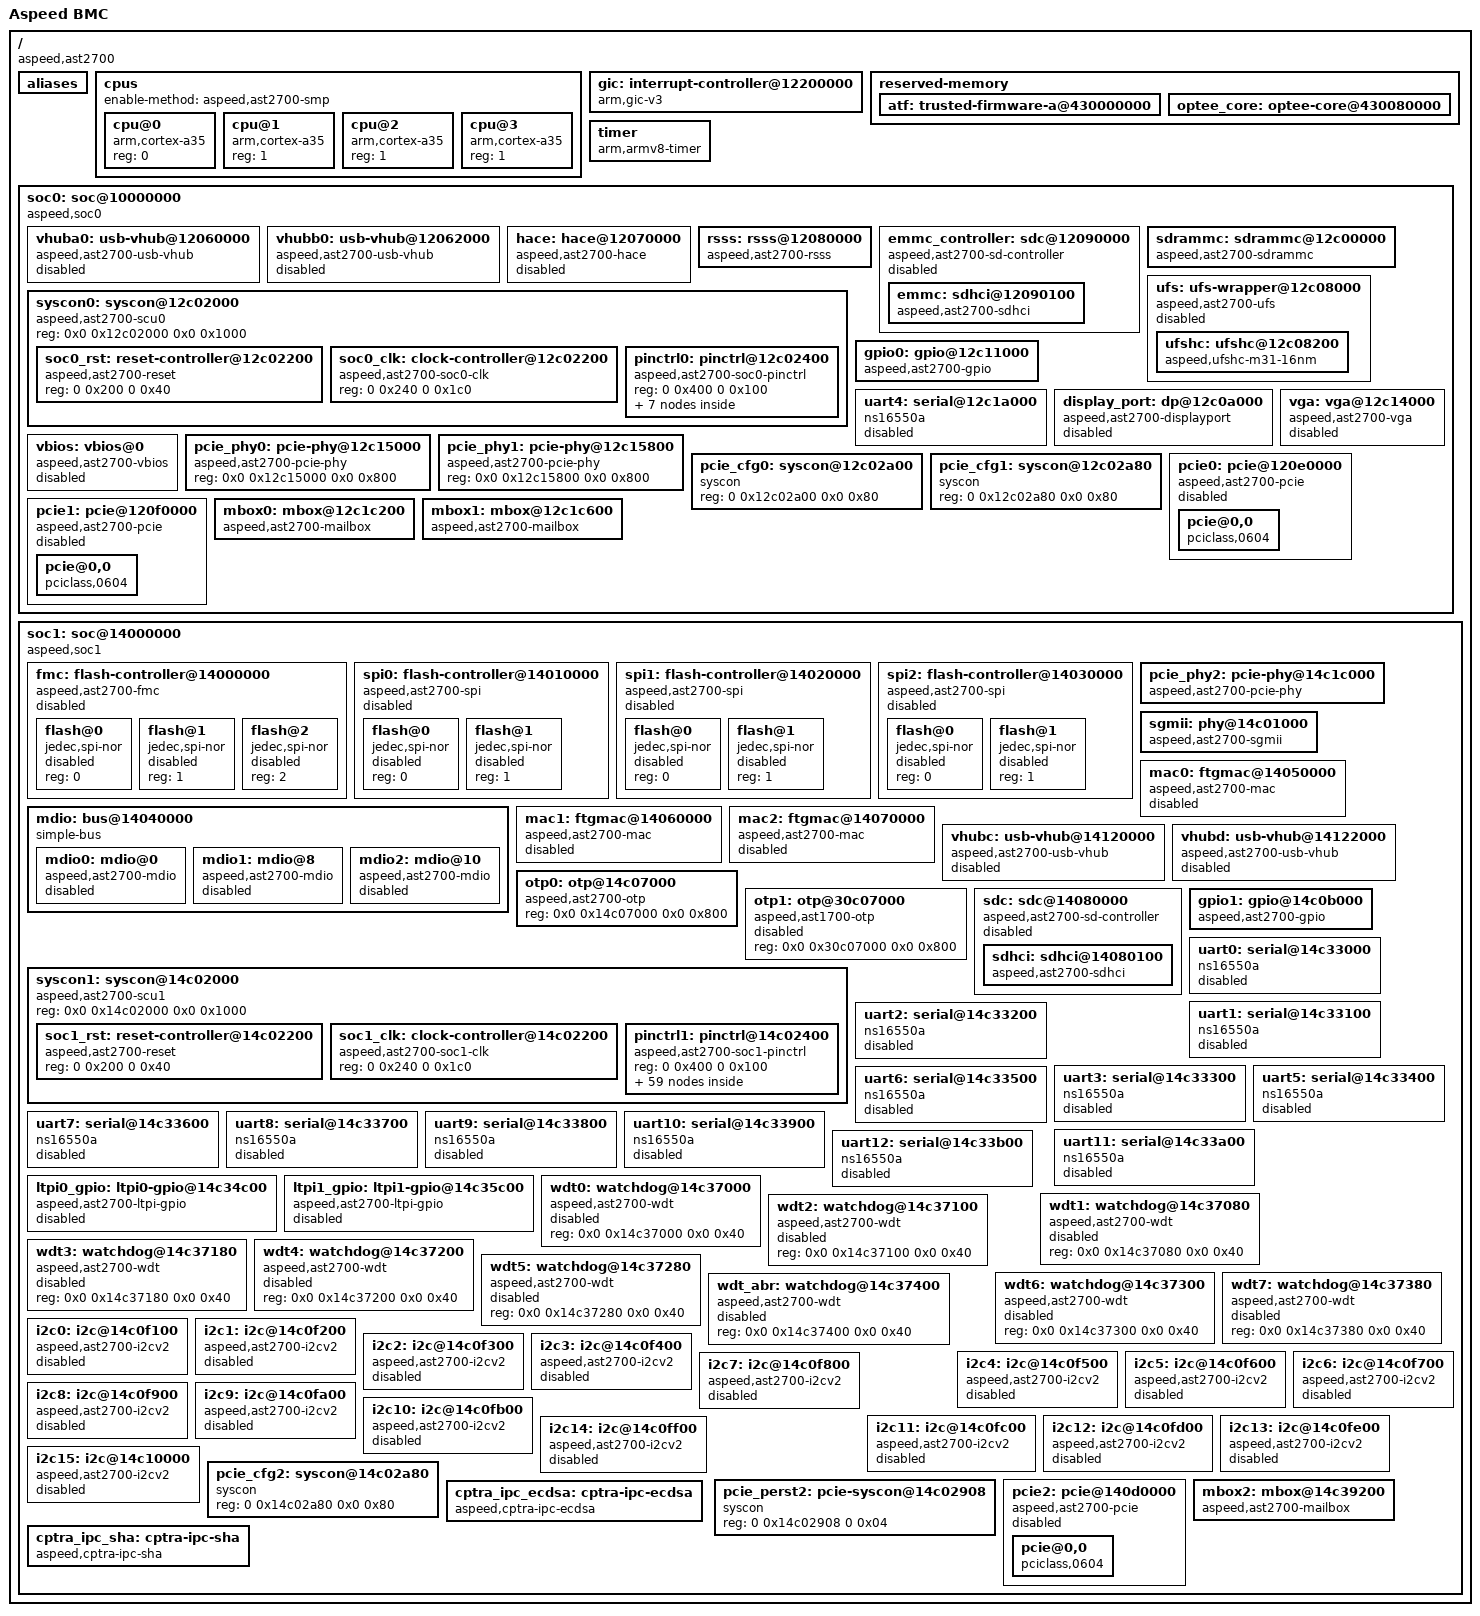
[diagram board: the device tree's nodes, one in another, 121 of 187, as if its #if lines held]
// SPDX-License-Identifier: GPL-2.0+
#include <dt-bindings/interrupt-controller/arm-gic.h>
#include <dt-bindings/gpio/aspeed-gpio.h>
#include <dt-bindings/clock/ast2700-clock.h>
#include <dt-bindings/phy/phy.h>
#include <dt-bindings/reset/ast2700-reset.h>
#include "skeleton.dtsi"

/ {
	model = "Aspeed BMC";
	compatible = "aspeed,ast2700";
	#address-cells = <2>;
	#size-cells = <2>;
	interrupt-parent = <&gic>;

	aliases {
		serial0 = &uart0;
		serial1 = &uart1;
		serial2 = &uart2;
		serial3 = &uart3;
		serial4 = &uart4;
		serial5 = &uart5;
		serial6 = &uart6;
		serial7 = &uart7;
		serial8 = &uart8;
		serial9 = &uart9;
		serial10 = &uart10;
		serial11 = &uart11;
		serial12 = &uart12;
		i2c0 = &i2c0;
		i2c1 = &i2c1;
		i2c2 = &i2c2;
		i2c3 = &i2c3;
		i2c4 = &i2c4;
		i2c5 = &i2c5;
		i2c6 = &i2c6;
		i2c7 = &i2c7;
		i2c8 = &i2c8;
		i2c9 = &i2c9;
		i2c10 = &i2c10;
		i2c11 = &i2c11;
		i2c12 = &i2c12;
		i2c13 = &i2c13;
		i2c14 = &i2c14;
		i2c15 = &i2c15;
		mmc0 = &emmc;
		mmc1 = &sdhci;
		ethernet0 = &mac0;
		ethernet1 = &mac1;
		ethernet2 = &mac2;
	};

	cpus {
		#address-cells = <1>;
		#size-cells = <0>;
		enable-method = "aspeed,ast2700-smp";

		cpu@0 {
			compatible = "arm,cortex-a35";
			device_type = "cpu";
			reg = <0>;
		};

		cpu@1 {
			compatible = "arm,cortex-a35";
			device_type = "cpu";
			reg = <1>;
		};

		cpu@2 {
			compatible = "arm,cortex-a35";
			device_type = "cpu";
			reg = <1>;
		};

		cpu@3 {
			compatible = "arm,cortex-a35";
			device_type = "cpu";
			reg = <1>;
		};

	};

	gic: interrupt-controller@12200000 {
		compatible = "arm,gic-v3";
		interrupts = <GIC_PPI 9 (GIC_CPU_MASK_SIMPLE(2) | IRQ_TYPE_LEVEL_HIGH)>;
		#interrupt-cells = <3>;
		interrupt-controller;
		interrupt-parent = <&gic>;
		#redistributor-regions = <1>;
		reg =	<0 0x12200000 0 0x10000>,		//GICD
			<0 0x12280000 0 0x80000>,		//GICR
			<0 0x40440000 0 0x1000>;		//GICC
	};

	reserved-memory {
		#address-cells = <2>;
		#size-cells = <2>;
		ranges;

		atf: trusted-firmware-a@430000000 {
			reg = <0x4 0x30000000 0x0 0x80000>;
			no-map;
		};

		optee_core: optee-core@430080000 {
			reg = <0x4 0x30080000 0x0 0x1000000>;
			no-map;
		};
	};

	timer {
		compatible = "arm,armv8-timer";
		interrupt-parent = <&gic>;
		interrupts = <GIC_PPI 13 (GIC_CPU_MASK_SIMPLE(2) | IRQ_TYPE_LEVEL_LOW)>,
				<GIC_PPI 14 (GIC_CPU_MASK_SIMPLE(2) | IRQ_TYPE_LEVEL_LOW)>,
				<GIC_PPI 11 (GIC_CPU_MASK_SIMPLE(2) | IRQ_TYPE_LEVEL_LOW)>,
				<GIC_PPI 10 (GIC_CPU_MASK_SIMPLE(2) | IRQ_TYPE_LEVEL_LOW)>;
	};

	soc0: soc@10000000 {
		compatible = "aspeed,soc0","simple-bus";
		#address-cells = <2>;
		#size-cells = <2>;
		ranges;

		vhuba0: usb-vhub@12060000 {
			compatible = "aspeed,ast2700-usb-vhub";
			reg = <0 0x12060000 0 0x350>;
			interrupts = <GIC_SPI 33 IRQ_TYPE_LEVEL_HIGH>;
			clocks = <&soc0_clk SCU0_CLK_GATE_PORTAUSB2CLK>;
			resets = <&soc0_rst SCU0_RESET_PORTA_VHUB_EHCI>;
			pinctrl-names = "default";
			pinctrl-0 = <&pinctrl_usb2ad_default>;
			status = "disabled";
		};

		vhubb0: usb-vhub@12062000 {
			compatible = "aspeed,ast2700-usb-vhub";
			reg = <0x0 0x12062000 0x0 0x350>;
			interrupts = <GIC_SPI 37 IRQ_TYPE_LEVEL_HIGH>;
			clocks = <&soc0_clk SCU0_CLK_GATE_PORTBUSB2CLK>;
			resets = <&soc0_rst SCU0_RESET_PORTB_VHUB_EHCI>;
			pinctrl-names = "default";
			pinctrl-0 = <&pinctrl_usb2bd_default>;
			status = "disabled";
		};

		hace: hace@12070000 {
			compatible = "aspeed,ast2700-hace";
			reg = <0 0x12070000 0 0x200>;
			clocks = <&soc0_clk SCU0_CLK_GATE_HACCLK>;
			resets = <&soc0_rst SCU0_RESET_HACE>;
			status = "disabled";
		};

		rsss: rsss@12080000 {
			compatible = "aspeed,ast2700-rsss";
			reg = <0 0x12080000 0 0x1000>;
			interrupts = <GIC_SPI 3 IRQ_TYPE_LEVEL_HIGH>;
			clocks = <&soc0_clk SCU0_CLK_GATE_RSACLK>;
			resets = <&soc0_rst SCU0_RESET_RSA>,
				 <&soc0_rst SCU0_RESET_SHA3>,
				 <&soc0_rst SCU0_RESET_SM3>,
				 <&soc0_rst SCU0_RESET_SM4>;
			reset-names = "rsa", "sha3", "sm3", "sm4";
		};

		emmc_controller: sdc@12090000 {
			compatible = "aspeed,ast2700-sd-controller";
			reg = <0 0x12090000 0 0x100>;
			#address-cells = <2>;
			#size-cells = <2>;
			clocks = <&soc0_clk SCU0_CLK_GATE_EMMCCLK>;
			resets = <&soc0_rst SCU0_RESET_EMMC>;
			ranges = <0 0 0 0x12090000 0 0x10000>;
			status = "disable";

			emmc: sdhci@12090100 {
				compatible = "aspeed,ast2700-sdhci";
				reg = <0 0x100 0 0x100>;
				sdhci,auto-cmd12;
				#interrupts = <GIC_SPI 15 IRQ_TYPE_LEVEL_HIGH>;
				clocks = <&soc0_clk SCU0_CLK_GATE_EMMCCLK>;
				pinctrl-names = "default";
				pinctrl-0 = <&pinctrl_emmc_default>;
			};
		};

		sdrammc: sdrammc@12c00000 {
			compatible = "aspeed,ast2700-sdrammc";
			reg = <0 0x12c00000 0 0x3000 0 0x13000000 0 0x300 >;
			clocks = <&soc0_clk SCU0_CLK_MPLL>;
			resets = <&soc0_rst SCU0_RESET_SDRAM>;
		};

		syscon0: syscon@12c02000 {
			compatible = "aspeed,ast2700-scu0", "syscon", "simple-mfd";
			reg = <0x0 0x12c02000 0x0 0x1000>;
			ranges = <0 0 0x0 0x12c02000 0x0 0x1000>;
			#address-cells = <2>;
			#size-cells = <2>;

			soc0_rst: reset-controller@12c02200 {
				compatible = "aspeed,ast2700-reset";
				reg = <0 0x200 0 0x40>;
				#reset-cells = <1>;
			};

			soc0_clk: clock-controller@12c02200 {
				compatible = "aspeed,ast2700-soc0-clk";
				reg = <0 0x240 0 0x1c0>;
				#clock-cells = <1>;
			};

			pinctrl0: pinctrl@12c02400 {
				compatible = "aspeed,ast2700-soc0-pinctrl";
				reg = <0 0x400 0 0x100>;
			};
		};

		ufs: ufs-wrapper@12c08000 {
			compatible = "aspeed,ast2700-ufs";
			reg = <0x0 0x12c08000 0x0 0x100>;
			#address-cells = <2>;
			#size-cells = <2>;
			ranges = <0 0 0 0x12c08000 0 0x400>;
			clocks = <&soc0_clk SCU0_CLK_GATE_UFSCLK>;
			resets = <&soc0_rst SCU0_RESET_UFS>;
			status = "disable";

			ufshc: ufshc@12c08200 {
				compatible = "aspeed,ufshc-m31-16nm", "jedec,ufs-2.0";
				reg = <0x0 0x200 0x0 0x100>;
				interrupts = <GIC_SPI 118 IRQ_TYPE_LEVEL_HIGH>;
				freq-table-hz = <400000000 400000000>;
				clocks = <&soc0_clk SCU0_CLK_AXI1>;
				clock-names = "core_clk";
				dma-coherent;
			};
		};

		gpio0: gpio@12c11000 {
			compatible = "aspeed,ast2700-gpio";
			reg = <0x0 0x12c11000 0x0 0x1000>;
			#gpio-cells = <2>;
			gpio-controller;
			gpio-ranges = <&pinctrl0 0 0 12>;
			ngpios = <12>;
		};

		uart4: serial@12c1a000 {
			compatible = "ns16550a";
			reg = <0x0 0x12c1a000 0x0 0x1000>;
			reg-shift = <2>;
			interrupts = <GIC_SPI 36 IRQ_TYPE_LEVEL_HIGH>;
			clocks = <&soc0_clk SCU0_CLK_GATE_UART4CLK>;
			no-loopback-test;
			status = "disabled";
		};

		display_port: dp@12c0a000 {
			compatible = "aspeed,ast2700-displayport";
			reg = <0x0 0x12c0a000 0x0 0x200>,
			      <0x0 0x11000000 0x0 0x1000>,
			      <0x0 0x11010000 0x0 0x100>,
			      <0x0 0x11020000 0x0 0x4000>;
			interrupts = <GIC_SPI 28 IRQ_TYPE_LEVEL_HIGH>;
			clocks = <&soc0_clk SCU0_CLK_GATE_DP>;
			resets = <&soc0_rst SCU0_RESET_DP>, <&soc0_rst SCU0_RESET_DP_MCU>;
			aspeed,scu = <&syscon0>;
			status = "disabled";
		};

		vga: vga@12c14000 {
			compatible = "aspeed,ast2700-vga";
			reg = <0 0x12c02000 0 0x1000>, <0 0x12c00000 0 0x200>,
			      <0 0x12c21000 0 0x200>, <0 0x12c22000 0 0x200>,
			      <0 0x12c1d000 0 0x200>, <0 0x14c3a000 0 0x200>;
			clocks = <&soc0_clk SCU0_CLK_GATE_VGA0CLK>,
				 <&soc0_clk SCU0_CLK_GATE_VGA1CLK>,
				 <&soc0_clk SCU0_CLK_GATE_DACCLK>;
			resets = <&soc0_rst SCU0_RESET_VLINK>;
			status = "disabled";
		};

		vbios: vbios@0 {
			compatible = "aspeed,ast2700-vbios";
			reg = <0 0x12c21100 0 0x100>,		// e2m0
			      <0 0x12c22100 0 0x100>;		// e2m1
			aspeed,scu = <&syscon0>;
			pinctrl-names = "default";
			pinctrl-0 = <&pinctrl_dacedid_default>;
			status = "disabled";
		};

		pcie_phy0: pcie-phy@12c15000 {
			compatible = "aspeed,ast2700-pcie-phy";
			reg = <0x0 0x12c15000 0x0 0x800>;
			#phy-cells = <1>;
		};

		pcie_phy1: pcie-phy@12c15800 {
			compatible = "aspeed,ast2700-pcie-phy";
			reg = <0x0 0x12c15800 0x0 0x800>;
			#phy-cells = <1>;
		};

		pcie_cfg0: syscon@12c02a00 {
			compatible = "syscon";
			reg = <0 0x12c02a00 0x0 0x80>;
		};

		pcie_cfg1: syscon@12c02a80 {
			compatible = "syscon";
			reg = <0 0x12c02a80 0x0 0x80>;
		};

		pcie0: pcie@120e0000 {
			compatible = "aspeed,ast2700-pcie";
			device_type = "pci";
			reg = <0x0 0x120e0000 0x0 0x100>;
			linux,pci-domain = <0>;
			#address-cells = <3>;
			#size-cells = <2>;
			bus-range = <0x00 0xff>;

			ranges = <0x02000000 0 0x60000000 0x0 0x60000000 0x0 0x10000000>;

			status = "disabled";

			resets = <&soc0_rst SCU0_RESET_H2X0>;
			reset-names = "h2x";

			aspeed,pciecfg = <&pcie_cfg0>;

			pcie@0,0 {
				compatible = "pciclass,0604";
				reg = <0 0 0 0 0>;
				#address-cells = <3>;
				#size-cells = <2>;
				device_type = "pci";
				resets = <&soc0_rst SCU0_RESET_PCIE0RST>,
					 <&soc0_rst SCU0_RESET_PCIE0RSTOE>;
				reset-names = "perst", "perst_oe";
				clocks = <&soc0_clk SCU0_CLK_GATE_BCLK>;
				phys = <&pcie_phy0 PHY_TYPE_PCIE>;
				ranges;
			};
		};

		pcie1: pcie@120f0000 {
			compatible = "aspeed,ast2700-pcie";
			device_type = "pci";
			reg = <0x0 0x120f0000 0x0 0x100>;
			linux,pci-domain = <1>;
			#address-cells = <3>;
			#size-cells = <2>;
			bus-range = <0x00 0xff>;

			ranges = <0x02000000 0 0x80000000 0x0 0x80000000 0x0 0x10000000>;

			status = "disabled";

			resets = <&soc0_rst SCU0_RESET_H2X1>;
			reset-names = "h2x";

			aspeed,pciecfg = <&pcie_cfg1>;

			pcie@0,0 {
				compatible = "pciclass,0604";
				reg = <0 0 0 0 0>;
				#address-cells = <3>;
				#size-cells = <2>;
				device_type = "pci";
				resets = <&soc0_rst SCU0_RESET_PCIE1RST>,
					 <&soc0_rst SCU0_RESET_PCIE1RSTOE>;
				reset-names = "perst", "perst_oe";
				clocks = <&soc0_clk SCU0_CLK_GATE_BCLK>;
				phys = <&pcie_phy1 PHY_TYPE_PCIE>;
				ranges;
			};
		};
		mbox0: mbox@12c1c200 {
			compatible = "aspeed,ast2700-mailbox";
			reg = <0x0 0x12c1c200 0x0 0x100>, <0x0 0x12c1c300 0x0 0x100>;
			reg-names = "tx", "rx";
			interrupts = <GIC_SPI 103 IRQ_TYPE_LEVEL_HIGH>;
			#mbox-cells = <1>;
			mbox-name = "ssp";
		};

		mbox1: mbox@12c1c600 {
			compatible = "aspeed,ast2700-mailbox";
			reg = <0x0 0x12c1c600 0x0 0x100>, <0x0 0x12c1c700 0x0 0x100>;
			reg-names = "tx", "rx";
			interrupts = <GIC_SPI 107 IRQ_TYPE_LEVEL_HIGH>;
			#mbox-cells = <1>;
			mbox-name = "tsp";
		};
	};

	soc1: soc@14000000 {
		compatible = "aspeed,soc1","simple-bus";
		#address-cells = <2>;
		#size-cells = <2>;
		ranges;

		fmc: flash-controller@14000000 {
			reg = <0x0 0x14000000 0x0 0xc4>,
			      <0x1 0x00000000 0x0 0x80000000>;
			#address-cells = <1>;
			#size-cells = <0>;
			compatible = "aspeed,ast2700-fmc";
			status = "disabled";
			clocks = <&soc1_clk SCU1_CLK_AHB>;
			num-cs = <3>;

			flash@0 {
				reg = <0>;
				compatible = "jedec,spi-nor";
				status = "disabled";
			};

			flash@1 {
				reg = <1>;
				compatible = "jedec,spi-nor";
				status = "disabled";
			};

			flash@2 {
				reg = <2>;
				compatible = "jedec,spi-nor";
				status = "disabled";
			};
		};

		spi0: flash-controller@14010000 {
			reg = <0x0 0x14010000 0x0 0xc4>,
			      <0x1 0x80000000 0x0 0x80000000>;
			#address-cells = <1>;
			#size-cells = <0>;
			compatible = "aspeed,ast2700-spi";
			status = "disabled";
			clocks = <&soc1_clk SCU1_CLK_AHB>;
			num-cs = <2>;

			flash@0 {
				reg = <0>;
				compatible = "jedec,spi-nor";
				status = "disabled";
			};

			flash@1 {
				reg = <1>;
				compatible = "jedec,spi-nor";
				status = "disabled";
			};
		};

		spi1: flash-controller@14020000 {
			reg = <0x0 0x14020000 0x0 0xc4>,
			      <0x2 0x00000000 0x0 0x80000000>;
			#address-cells = <1>;
			#size-cells = <0>;
			compatible = "aspeed,ast2700-spi";
			status = "disabled";
			clocks = <&soc1_clk SCU1_CLK_AHB>;
			num-cs = <2>;

			flash@0 {
				reg = <0>;
				compatible = "jedec,spi-nor";
				status = "disabled";
			};

			flash@1 {
				reg = <1>;
				compatible = "jedec,spi-nor";
				status = "disabled";
			};
		};

		spi2: flash-controller@14030000 {
			reg = <0x0 0x14030000 0x0 0xc4>,
			      <0x2 0x80000000 0x0 0x80000000>;
			#address-cells = <1>;
			#size-cells = <0>;
			compatible = "aspeed,ast2700-spi";
			status = "disabled";
			clocks = <&soc1_clk SCU1_CLK_AHB>;
			resets = <&soc1_rst SCU1_RESET_SPI2>;
			num-cs = <2>;

			flash@0 {
				reg = <0>;
				compatible = "jedec,spi-nor";
				status = "disabled";
			};

			flash@1 {
				reg = <1>;
				compatible = "jedec,spi-nor";
				status = "disabled";
			};
		};

		mdio: bus@14040000 {
			compatible = "simple-bus";
			#address-cells = <2>;
			#size-cells = <2>;
			ranges = <0 0 0 0x14040000 0 0x100>;

			mdio0: mdio@0 {
				compatible = "aspeed,ast2700-mdio";
				reg = <0 0 0 0x8>;
				resets = <&soc1_rst SCU1_RESET_MII>;
				pinctrl-names = "default";
				pinctrl-0 = <&pinctrl_mdio0_default>;
				status = "disabled";
			};

			mdio1: mdio@8 {
				compatible = "aspeed,ast2700-mdio";
				reg = <0 0x8 0 0x8>;
				resets = <&soc1_rst SCU1_RESET_MII>;
				pinctrl-names = "default";
				pinctrl-0 = <&pinctrl_mdio1_default>;
				status = "disabled";
			};

			mdio2: mdio@10 {
				compatible = "aspeed,ast2700-mdio";
				reg = <0 0x10 0 0x8>;
				resets = <&soc1_rst SCU1_RESET_MII>;
				pinctrl-names = "default";
				pinctrl-0 = <&pinctrl_mdio2_default>;
				status = "disabled";
			};
		};

		pcie_phy2: pcie-phy@14c1c000 {
			compatible = "aspeed,ast2700-pcie-phy";
			reg = <0x0 0x14c1c000 0x0 0x400>;
			#phy-cells = <1>;
			aspeed,scu = <&syscon1>;
		};

		sgmii: phy@14c01000 {
			compatible = "aspeed,ast2700-sgmii";
			reg = <0x0 0x14c01000 0x0 0x40>;
			#phy-cells = <0>;

			phys = <&pcie_phy2 PHY_TYPE_SGMII>;
			aspeed,scu = <&syscon1>;

			pinctrl-names = "default";
			pinctrl-0 = <&pinctrl_sgmii_default>;
		};

		mac0: ftgmac@14050000 {
			compatible = "aspeed,ast2700-mac", "faraday,ftgmac100";
			reg = <0x0 0x14050000 0x0 0x200>;
			clocks = <&soc1_clk SCU1_CLK_GATE_MAC0CLK>;
			resets = <&soc1_rst SCU1_RESET_MAC0>;
			aspeed,scu = <&syscon1>;
			status = "disabled";
		};

		mac1: ftgmac@14060000 {
			compatible = "aspeed,ast2700-mac", "faraday,ftgmac100";
			reg = <0x0 0x14060000 0x0 0x200>;
			clocks = <&soc1_clk SCU1_CLK_GATE_MAC1CLK>;
			resets = <&soc1_rst SCU1_RESET_MAC1>;
			aspeed,scu = <&syscon1>;
			status = "disabled";
		};

		mac2: ftgmac@14070000 {
			compatible = "aspeed,ast2700-mac", "faraday,ftgmac100";
			reg = <0x0 0x14070000 0x0 0x200>;

			phys = <&sgmii>;
			phy-names = "sgmii";

			phy-mode = "sgmii"; /* Only support sgmii mode */

			clocks = <&soc1_clk SCU1_CLK_GATE_MAC2CLK>;
			resets = <&soc1_rst SCU1_RESET_MAC2>;
			aspeed,scu = <&syscon1>;
			status = "disabled";
		};

		vhubc: usb-vhub@14120000 {
			compatible = "aspeed,ast2700-usb-vhub";
			reg = <0x0 0x14120000 0x0 0x350>;
			clocks = <&soc1_clk SCU1_CLK_GATE_PORTCUSB2CLK>;
			resets = <&soc1_rst SCU1_RESET_PORTC_VHUB_EHCI>;
			pinctrl-names = "default";
			pinctrl-0 = <&pinctrl_usb2cd_default>;
			status = "disabled";
		};

		vhubd: usb-vhub@14122000 {
			compatible = "aspeed,ast2700-usb-vhub";
			reg = <0x0 0x14122000 0x0 0x350>;
			clocks = <&soc1_clk SCU1_CLK_GATE_PORTDUSB2CLK>;
			resets = <&soc1_rst SCU1_RESET_PORTD_VHUB_EHCI>;
			pinctrl-names = "default";
			pinctrl-0 = <&pinctrl_usb2dd_default>;
			status = "disabled";
		};

		otp0: otp@14c07000 {
			compatible = "aspeed,ast2700-otp";
			reg = <0x0 0x14c07000 0x0 0x800>;
		};

		otp1: otp@30c07000 {
			compatible = "aspeed,ast1700-otp";
			reg = <0x0 0x30c07000 0x0 0x800>;
			status = "disabled";
		};

		sdc: sdc@14080000 {
			compatible = "aspeed,ast2700-sd-controller";
			reg = <0 0x14080000 0 0x100>;
			#address-cells = <2>;
			#size-cells = <2>;
			clocks = <&soc1_clk SCU1_CLK_GATE_SDCLK>;
			resets = <&soc1_rst SCU1_RESET_SD>;
			ranges = <0 0 0 0x14080000 0 0x10000>;
			status = "disable";

			sdhci: sdhci@14080100 {
				compatible = "aspeed,ast2700-sdhci";
				reg = <0 0x100 0 0x100>;
				clocks = <&soc1_clk SCU1_CLK_GATE_SDCLK>;
			};
		};

		syscon1: syscon@14c02000 {
			compatible = "aspeed,ast2700-scu1", "syscon", "simple-mfd";
			reg = <0x0 0x14c02000 0x0 0x1000>;
			ranges = <0 0 0 0x14c02000 0 0x1000>;
			#address-cells = <2>;
			#size-cells = <2>;

			soc1_rst: reset-controller@14c02200 {
				compatible = "aspeed,ast2700-reset";
				reg = <0 0x200 0 0x40>;
				#reset-cells = <1>;
			};

			soc1_clk: clock-controller@14c02200 {
				compatible = "aspeed,ast2700-soc1-clk";
				reg = <0 0x240 0 0x1c0>;
				#clock-cells = <1>;
			};

			pinctrl1: pinctrl@14c02400 {
				compatible = "aspeed,ast2700-soc1-pinctrl";
				reg = <0 0x400 0 0x100>;
			};
		};

		gpio1: gpio@14c0b000 {
			compatible = "aspeed,ast2700-gpio";
			reg = <0x0 0x14c0b000 0x0 0x1000>;
			#gpio-cells = <2>;
			gpio-controller;
			gpio-ranges = <&pinctrl1 0 0 216>;
			ngpios = <244>;
		};

		uart0: serial@14c33000 {
			compatible = "ns16550a";
			reg = <0x0 0x14c33000 0x0 0x20>;
			reg-shift = <2>;
			clocks = <&soc1_clk SCU1_CLK_GATE_UART0CLK>;
			no-loopback-test;
			status = "disabled";
		};

		uart1: serial@14c33100 {
			compatible = "ns16550a";
			reg = <0x0 0x14c33100 0x0 0x20>;
			reg-shift = <2>;
			clocks = <&soc1_clk SCU1_CLK_GATE_UART1CLK>;
			no-loopback-test;
			status = "disabled";
		};

		uart2: serial@14c33200 {
			compatible = "ns16550a";
			reg = <0x0 0x14c33200 0x0 0x20>;
			reg-shift = <2>;
			clocks = <&soc1_clk SCU1_CLK_GATE_UART2CLK>;
			no-loopback-test;
			status = "disabled";
		};

		uart3: serial@14c33300 {
			compatible = "ns16550a";
			reg = <0x0 0x14c33300 0x0 0x20>;
			reg-shift = <2>;
			clocks = <&soc1_clk SCU1_CLK_GATE_UART3CLK>;
			no-loopback-test;
			status = "disabled";
		};

		uart5: serial@14c33400 {
			compatible = "ns16550a";
			reg = <0x0 0x14c33400 0x0 0x20>;
			reg-shift = <2>;
			clocks = <&soc1_clk SCU1_CLK_GATE_UART5CLK>;
			no-loopback-test;
			status = "disabled";
		};

		uart6: serial@14c33500 {
			compatible = "ns16550a";
			reg = <0x0 0x14c33500 0x0 0x20>;
			reg-shift = <2>;
			clocks = <&soc1_clk SCU1_CLK_GATE_UART6CLK>;
			no-loopback-test;
			status = "disabled";
		};

		uart7: serial@14c33600 {
			compatible = "ns16550a";
			reg = <0x0 0x14c33600 0x0 0x20>;
			reg-shift = <2>;
			clocks = <&soc1_clk SCU1_CLK_GATE_UART7CLK>;
			no-loopback-test;
			status = "disabled";
		};

		uart8: serial@14c33700 {
			compatible = "ns16550a";
			reg = <0x0 0x14c33700 0x0 0x20>;
			reg-shift = <2>;
			clocks = <&soc1_clk SCU1_CLK_GATE_UART8CLK>;
			no-loopback-test;
			status = "disabled";
		};

		uart9: serial@14c33800 {
			compatible = "ns16550a";
			reg = <0x0 0x14c33800 0x0 0x20>;
			reg-shift = <2>;
			clocks = <&soc1_clk SCU1_CLK_GATE_UART9CLK>;
			no-loopback-test;
			status = "disabled";
		};

		uart10: serial@14c33900 {
			compatible = "ns16550a";
			reg = <0x0 0x14c33900 0x0 0x20>;
			reg-shift = <2>;
			clocks = <&soc1_clk SCU1_CLK_GATE_UART10CLK>;
			no-loopback-test;
			status = "disabled";
		};

		uart11: serial@14c33a00 {
			compatible = "ns16550a";
			reg = <0x0 0x14c33a00 0x0 0x20>;
			reg-shift = <2>;
			clocks = <&soc1_clk SCU1_CLK_GATE_UART11CLK>;
			no-loopback-test;
			status = "disabled";
		};

		uart12: serial@14c33b00 {
			compatible = "ns16550a";
			reg = <0x0 0x14c33b00 0x0 0x20>;
			reg-shift = <2>;
			clocks = <&soc1_clk SCU1_CLK_GATE_UART12CLK>;
			clock-frequency = <1846154>;
			no-loopback-test;
			status = "disabled";
		};

		ltpi0_gpio: ltpi0-gpio@14c34c00 {
			compatible = "aspeed,ast2700-ltpi-gpio";
			reg = <0x0 0x14c34c00 0x0 0x300>;
			#gpio-cells = <2>;
			gpio-controller;
			ngpios = <112>;
			status = "disabled";
		};

		ltpi1_gpio: ltpi1-gpio@14c35c00 {
			compatible = "aspeed,ast2700-ltpi-gpio";
			reg = <0x0 0x14c35c00 0x0 0x300>;
			#gpio-cells = <2>;
			gpio-controller;
			ngpios = <112>;
			status = "disabled";
		};

		wdt0: watchdog@14c37000 {
			compatible = "aspeed,ast2700-wdt";
			reg = <0x0 0x14c37000 0x0 0x40>;
			status = "disabled";
		};

		wdt1: watchdog@14c37080 {
			compatible = "aspeed,ast2700-wdt";
			reg = <0x0 0x14c37080 0x0 0x40>;
			status = "disabled";
		};

		wdt2: watchdog@14c37100 {
			compatible = "aspeed,ast2700-wdt";
			reg = <0x0 0x14c37100 0x0 0x40>;
			status = "disabled";
		};

		wdt3: watchdog@14c37180 {
			compatible = "aspeed,ast2700-wdt";
			reg = <0x0 0x14c37180 0x0 0x40>;
			status = "disabled";
		};

		wdt4: watchdog@14c37200 {
			compatible = "aspeed,ast2700-wdt";
			reg = <0x0 0x14c37200 0x0 0x40>;
			status = "disabled";
		};

		wdt5: watchdog@14c37280 {
			compatible = "aspeed,ast2700-wdt";
			reg = <0x0 0x14c37280 0x0 0x40>;
			status = "disabled";
		};

		wdt6: watchdog@14c37300 {
			compatible = "aspeed,ast2700-wdt";
			reg = <0x0 0x14c37300 0x0 0x40>;
			status = "disabled";
		};

		wdt7: watchdog@14c37380 {
			compatible = "aspeed,ast2700-wdt";
			reg = <0x0 0x14c37380 0x0 0x40>;
			status = "disabled";
		};

		wdt_abr: watchdog@14c37400 {
			compatible = "aspeed,ast2700-wdt";
			reg = <0x0 0x14c37400 0x0 0x40>;
			status = "disabled";
		};

		i2c0: i2c@14c0f100 {
			reg = <0 0x14c0f100 0 0x40>;
			compatible = "aspeed,ast2700-i2cv2";
			bus-frequency = <100000>;
			resets = <&soc1_rst SCU1_RESET_I2C>;
			clocks = <&soc1_clk SCU1_CLK_APB>;
			pinctrl-names = "default";
			pinctrl-0 = <&pinctrl_i2c0_default>;
			status = "disabled";
		};

		i2c1: i2c@14c0f200 {
			reg = <0 0x14c0f200 0 0x40>;
			compatible = "aspeed,ast2700-i2cv2";
			bus-frequency = <100000>;
			resets = <&soc1_rst SCU1_RESET_I2C>;
			clocks = <&soc1_clk SCU1_CLK_APB>;
			pinctrl-names = "default";
			pinctrl-0 = <&pinctrl_i2c1_default>;
			status = "disabled";
		};

		i2c2: i2c@14c0f300 {
			reg = <0 0x14c0f300 0 0x40>;
			compatible = "aspeed,ast2700-i2cv2";
			bus-frequency = <100000>;
			resets = <&soc1_rst SCU1_RESET_I2C>;
			clocks = <&soc1_clk SCU1_CLK_APB>;
			pinctrl-names = "default";
			pinctrl-0 = <&pinctrl_i2c2_default>;
			status = "disabled";
		};

		i2c3: i2c@14c0f400 {
			reg = <0 0x14c0f400 0 0x40>;
			compatible = "aspeed,ast2700-i2cv2";
			bus-frequency = <100000>;
			resets = <&soc1_rst SCU1_RESET_I2C>;
			clocks = <&soc1_clk SCU1_CLK_APB>;
			pinctrl-names = "default";
			pinctrl-0 = <&pinctrl_i2c3_default>;
			status = "disabled";
		};

		i2c4: i2c@14c0f500 {
			reg = <0 0x14c0f500 0 0x40>;
			compatible = "aspeed,ast2700-i2cv2";
			bus-frequency = <100000>;
			resets = <&soc1_rst SCU1_RESET_I2C>;
			clocks = <&soc1_clk SCU1_CLK_APB>;
			pinctrl-names = "default";
			pinctrl-0 = <&pinctrl_i2c4_default>;
			status = "disabled";
		};

		i2c5: i2c@14c0f600 {
			reg = <0 0x14c0f600 0 0x40>;
			compatible = "aspeed,ast2700-i2cv2";
			bus-frequency = <100000>;
			resets = <&soc1_rst SCU1_RESET_I2C>;
			clocks = <&soc1_clk SCU1_CLK_APB>;
			pinctrl-names = "default";
			pinctrl-0 = <&pinctrl_i2c5_default>;
			status = "disabled";
		};

		i2c6: i2c@14c0f700 {
			reg = <0 0x14c0f700 0 0x40>;
			compatible = "aspeed,ast2700-i2cv2";
			bus-frequency = <100000>;
			resets = <&soc1_rst SCU1_RESET_I2C>;
			clocks = <&soc1_clk SCU1_CLK_APB>;
			pinctrl-names = "default";
			pinctrl-0 = <&pinctrl_i2c6_default>;
			status = "disabled";
		};

		i2c7: i2c@14c0f800 {
			reg = <0 0x14c0f800 0 0x40>;
			compatible = "aspeed,ast2700-i2cv2";
			bus-frequency = <100000>;
			resets = <&soc1_rst SCU1_RESET_I2C>;
			clocks = <&soc1_clk SCU1_CLK_APB>;
			pinctrl-names = "default";
			pinctrl-0 = <&pinctrl_i2c7_default>;
			status = "disabled";
		};

		i2c8: i2c@14c0f900 {
			reg = <0 0x14c0f900 0 0x40>;
			compatible = "aspeed,ast2700-i2cv2";
			bus-frequency = <100000>;
			resets = <&soc1_rst SCU1_RESET_I2C>;
			clocks = <&soc1_clk SCU1_CLK_APB>;
			pinctrl-names = "default";
			pinctrl-0 = <&pinctrl_i2c8_default>;
			status = "disabled";
		};

		i2c9: i2c@14c0fa00 {
			reg = <0 0x14c0fa00 0 0x40>;
			compatible = "aspeed,ast2700-i2cv2";
			bus-frequency = <100000>;
			resets = <&soc1_rst SCU1_RESET_I2C>;
			clocks = <&soc1_clk SCU1_CLK_APB>;
			pinctrl-names = "default";
			pinctrl-0 = <&pinctrl_i2c9_default>;
			status = "disabled";
		};

		i2c10: i2c@14c0fb00 {
			reg = <0 0x14c0fb00 0 0x40>;
			compatible = "aspeed,ast2700-i2cv2";
			bus-frequency = <100000>;
			resets = <&soc1_rst SCU1_RESET_I2C>;
			clocks = <&soc1_clk SCU1_CLK_APB>;
			pinctrl-names = "default";
			pinctrl-0 = <&pinctrl_i2c10_default>;
			status = "disabled";
		};

		i2c11: i2c@14c0fc00 {
			reg = <0 0x14c0fc00 0 0x40>;
			compatible = "aspeed,ast2700-i2cv2";
			bus-frequency = <100000>;
			resets = <&soc1_rst SCU1_RESET_I2C>;
			clocks = <&soc1_clk SCU1_CLK_APB>;
			pinctrl-names = "default";
			pinctrl-0 = <&pinctrl_i2c11_default>;
			status = "disabled";
		};

		i2c12: i2c@14c0fd00 {
			reg = <0 0x14c0fd00 0 0x40>;
			compatible = "aspeed,ast2700-i2cv2";
			bus-frequency = <100000>;
			resets = <&soc1_rst SCU1_RESET_I2C>;
			clocks = <&soc1_clk SCU1_CLK_APB>;
			pinctrl-names = "default";
			pinctrl-0 = <&pinctrl_i2c12_default>;
			status = "disabled";
		};

		i2c13: i2c@14c0fe00 {
			reg = <0 0x14c0fe00 0 0x40>;
			compatible = "aspeed,ast2700-i2cv2";
			bus-frequency = <100000>;
			resets = <&soc1_rst SCU1_RESET_I2C>;
			clocks = <&soc1_clk SCU1_CLK_APB>;
			pinctrl-names = "default";
			pinctrl-0 = <&pinctrl_i2c13_default>;
			status = "disabled";
		};

		i2c14: i2c@14c0ff00 {
			reg = <0 0x14c0ff00 0 0x40>;
			compatible = "aspeed,ast2700-i2cv2";
			bus-frequency = <100000>;
			resets = <&soc1_rst SCU1_RESET_I2C>;
			clocks = <&soc1_clk SCU1_CLK_APB>;
			pinctrl-names = "default";
			pinctrl-0 = <&pinctrl_i2c14_default>;
			status = "disabled";
		};

		i2c15: i2c@14c10000 {
			reg = <0 0x14c10000 0 0x40>;
			compatible = "aspeed,ast2700-i2cv2";
			bus-frequency = <100000>;
			resets = <&soc1_rst SCU1_RESET_I2C>;
			clocks = <&soc1_clk SCU1_CLK_APB>;
			pinctrl-names = "default";
			pinctrl-0 = <&pinctrl_i2c15_default>;
			status = "disabled";
		};

		pcie_cfg2: syscon@14c02a80 {
			compatible = "syscon";
			reg = <0 0x14c02a80 0x0 0x80>;
		};

		pcie_perst2: pcie-syscon@14c02908 {
			compatible = "syscon";
			reg = <0 0x14c02908 0 0x04>;
		};

		pcie2: pcie@140d0000 {
			compatible = "aspeed,ast2700-pcie";
			device_type = "pci";
			reg = <0x0 0x140d0000 0x0 0x100>;
			linux,pci-domain = <2>;
			#address-cells = <3>;
			#size-cells = <2>;
			bus-range = <0x00 0xff>;

			ranges = <0x02000000 0 0xa0000000 0x0 0xa0000000 0x0 0x10000000>;

			status = "disabled";

			resets = <&soc1_rst SCU1_RESET_H2X>;
			reset-names = "h2x";

			aspeed,pciecfg = <&pcie_cfg2>;

			pcie@0,0 {
				compatible = "pciclass,0604";
				reg = <0 0 0 0 0>;
				#address-cells = <3>;
				#size-cells = <2>;
				device_type = "pci";
				clocks = <&soc1_clk SCU1_CLK_GATE_PCICLK>;
				pinctrl-0 = <&pinctrl_pcie2_perst_default>;
				pinctrl-names = "default";
				phys = <&pcie_phy2 PHY_TYPE_PCIE>;
				aspeed,perst = <&pcie_perst2>;
				ranges;
			};
		};

		mbox2: mbox@14c39200 {
			compatible = "aspeed,ast2700-mailbox";
			reg = <0x0 0x14c39200 0x0 0x100>, <0x0 0x14c39300 0x0 0x100>;
			reg-names = "tx", "rx";
			#mbox-cells = <1>;
			mbox-name = "bootmcu";
			aspeed,tx-timeout = <1000>;
		};

		cptra_ipc_ecdsa: cptra-ipc-ecdsa {
			compatible = "aspeed,cptra-ipc-ecdsa";
		};

		cptra_ipc_sha: cptra-ipc-sha {
			compatible = "aspeed,cptra-ipc-sha";
		};
	};
};

&pinctrl0 {
	pinctrl_emmc_default: emmc_default {
		function = "EMMC";
		groups = "EMMC";
	};

	pinctrl_emmc8bit_default: emmc8bit_default {
		function = "EMMC8BIT";
		groups = "EMMC8BIT";
	};

	pinctrl_dacedid_default: dacedid_default {
		function = "DACEDID";
		groups = "DACEDID";
	};

	pinctrl_usb2ad_default: usb2ad_default {
		function = "USB2AD";
		groups = "USB2AD";
	};

	pinctrl_usb2ah_default: usb2ah_default {
		function = "USB2AH";
		groups = "USB2AH";
	};

	pinctrl_usb2bd_default: usb2bd_default {
		function = "USB2BD";
		groups = "USB2BD";
	};

	pinctrl_usb2bh_default: usb2bh_default {
		function = "USB2BH";
		groups = "USB2BH";
	};
};

&pinctrl1 {
	pinctrl_i2c0_default: i2c0_default {
		function = "I2C0";
		groups = "I2C0";
	};

	pinctrl_i2c1_default: i2c1_default {
		function = "I2C1";
		groups = "I2C1";
	};

	pinctrl_i2c2_default: i2c2_default {
		function = "I2C2";
		groups = "I2C2";
	};

	pinctrl_i2c3_default: i2c3_default {
		function = "I2C3";
		groups = "I2C3";
	};

	pinctrl_i2c4_default: i2c4_default {
		function = "I2C4";
		groups = "I2C4";
	};

	pinctrl_i2c5_default: i2c5_default {
		function = "I2C5";
		groups = "I2C5";
	};

	pinctrl_i2c6_default: i2c6_default {
		function = "I2C6";
		groups = "I2C6";
	};

	pinctrl_i2c7_default: i2c7_default {
		function = "I2C7";
		groups = "I2C7";
	};

	pinctrl_i2c8_default: i2c8_default {
		function = "I2C8";
		groups = "I2C8";
	};

	pinctrl_i2c9_default: i2c9_default {
		function = "I2C9";
		groups = "I2C9";
	};

	pinctrl_i2c10_default: i2c10_default {
		function = "I2C10";
		groups = "I2C10";
	};

	pinctrl_i2c11_default: i2c11_default {
		function = "I2C11";
		groups = "I2C11";
	};

	pinctrl_i2c12_default: i2c12_default {
		function = "I2C12";
		groups = "I2C12";
	};

	pinctrl_i2c13_default: i2c13_default {
		function = "I2C13";
		groups = "I2C13";
	};

	pinctrl_i2c14_default: i2c14_default {
		function = "I2C14";
		groups = "I2C14";
	};

	pinctrl_i2c15_default: i2c15_default {
		function = "I2C15";
		groups = "I2C15";
	};

	pinctrl_di2c0_default: di2c0_default {
		function = "DI2C0";
		groups = "DI2C0";
	};

	pinctrl_di2c1_default: di2c1_default {
		function = "DI2C1";
		groups = "DI2C1";
	};

	pinctrl_di2c2_default: di2c2_default {
		function = "DI2C2";
		groups = "DI2C2";
	};

	pinctrl_di2c3_default: di2c3_default {
		function = "DI2C3";
		groups = "DI2C3";
	};

	pinctrl_di2c8_default: di2c8_default {
		function = "DI2C8";
		groups = "DI2C8";
	};

	pinctrl_di2c9_default: di2c9_default {
		function = "DI2C9";
		groups = "DI2C9";
	};

	pinctrl_di2c10_default: di2c10_default {
		function = "DI2C10";
		groups = "DI2C10";
	};

	pinctrl_di2c11_default: di2c11_default {
		function = "DI2C11";
		groups = "DI2C11";
	};

	pinctrl_di2c12_default: di2c12_default {
		function = "DI2C12";
		groups = "DI2C12";
	};

	pinctrl_di2c13_default: di2c13_default {
		function = "DI2C13";
		groups = "DI2C13";
	};

	pinctrl_di2c14_default: di2c14_default {
		function = "DI2C14";
		groups = "DI2C14";
	};

	pinctrl_di2c15_default: di2c15_default {
		function = "DI2C15";
		groups = "DI2C15";
	};

	pinctrl_mac0link_default: mac0link_default {
		function = "MAC0LINK";
		groups = "MAC0LINK";
	};

	pinctrl_mac1link_default: mac1link_default {
		function = "MAC1LINK";
		groups = "MAC1LINK";
	};

	pinctrl_mac2link_default: mac2link_default {
		function = "MAC2LINK";
		groups = "MAC2LINK";
	};

	pinctrl_mdio0_default: mdio0_default {
		function = "MDIO0";
		groups = "MDIO0";
	};

	pinctrl_mdio1_default: mdio1_default {
		function = "MDIO1";
		groups = "MDIO1";
	};

	pinctrl_mdio2_default: mdio2_default {
		function = "MDIO2";
		groups = "MDIO2";
	};

	pinctrl_rgmii0_default: rgmii0_default {
		function = "RGMII0";
		groups = "RGMII0";
	};

	pinctrl_rgmii1_default: rgmii1_default {
		function = "RGMII1";
		groups = "RGMII1";
	};

	pinctrl_rmii0_default: rmii0_default {
		function = "RMII0";
		groups = "RMII0";
	};

	pinctrl_rmii0_rclko_default: rmii0-rclko-default {
		function = "RMII0RCLKO";
		groups = "RMII0RCLKO";
	};

	pinctrl_rmii1_default: rmii1_default {
		function = "RMII1";
		groups = "RMII1";
	};

	pinctrl_rmii1_rclko_default: rmii1-rclko-default {
		function = "RMII1RCLKO";
		groups = "RMII1RCLKO";
	};

	pinctrl_sgmii_default: sgmii_default {
		function = "SGMII";
		groups = "SGMII";
	};

	pinctrl_fwspi_quad_default: fwspi_quad_default {
		function = "FWSPIQUAD";
		groups = "FWSPIQUAD";
	};

	pinctrl_spi0_default: spi0_default {
		function = "SPI0";
		groups = "SPI0";
	};

	pinctrl_spi0_cs1_default: spi0_cs1_default {
		function = "SPI0CS1";
		groups = "SPI0CS1";
	};

	pinctrl_spi0_quad_default: spi0_quad_default {
		function = "SPI0QUAD";
		groups = "SPI0QUAD";
	};

	pinctrl_spi1_default: spi1_default {
		function = "SPI1";
		groups = "SPI1";
	};

	pinctrl_spi1_cs1_default: spi1_cs1_default {
		function = "SPI1CS1";
		groups = "SPI1CS1";
	};

	pinctrl_spi1_quad_default: spi1_quad_default {
		function = "SPI1QUAD";
		groups = "SPI1QUAD";
	};

	pinctrl_spi2_default: spi2_default {
		function = "SPI2";
		groups = "SPI2";
	};

	pinctrl_spi2_cs1_default: spi2_cs1_default {
		function = "SPI2CS1";
		groups = "SPI2CS1";
	};

	pinctrl_spi2_quad_default: spi2_quad_default {
		function = "SPI1QUAD";
		groups = "SPI1QUAD";
	};

	pinctrl_sdio_default: sdio_default {
		function = "SD";
		groups = "SD";
	};

	pinctrl_pcie2_perst_default: pcie2_perst_default {
		function = "PCIE2PERST";
		groups = "PCIE2PERST";
	};

	pinctrl_usb2cud_default: usb2cud_default {
		function = "USB2CUD";
		groups = "USB2CUD";
	};

	pinctrl_usb2cd_default: usb2cd_default {
		function = "USB2CD";
		groups = "USB2CD";
	};

	pinctrl_usb2ch_default: usb2ch_default {
		function = "USB2CH";
		groups = "USB2CH";
	};

	pinctrl_usb2cu_default: usb2cu_default {
		function = "USB2CU";
		groups = "USB2CU";
	};

	pinctrl_usb2dd_default: usb2dd_default {
		function = "USB2DD";
		groups = "USB2DD";
	};

	pinctrl_usb2dh_default: usb2dh_default {
		function = "USB2DH";
		groups = "USB2DH";
	};
};

#ifdef CONFIG_ASPEED_DP
#include "ast2700-dp-fw.dtsi"
#endif
